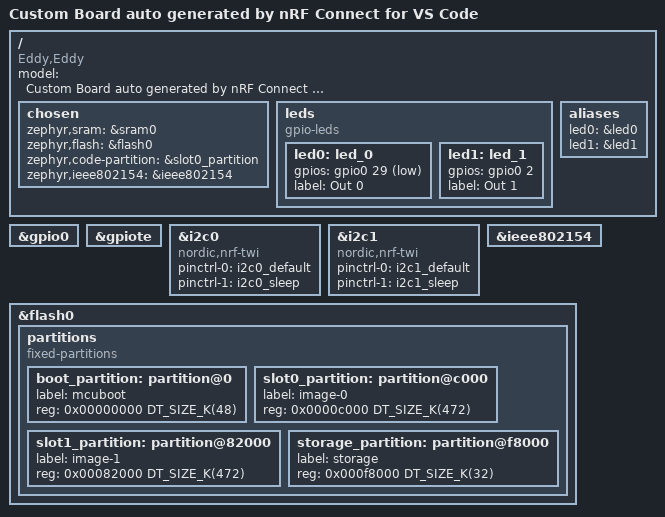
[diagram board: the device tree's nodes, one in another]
/dts-v1/;
#include <nordic/nrf52840_qiaa.dtsi>
#include "Eddy-pinctrl.dtsi"

/ {
	model = "Custom Board auto generated by nRF Connect for VS Code";
	compatible = "Eddy,Eddy";

	chosen {
		zephyr,sram = &sram0;
		zephyr,flash = &flash0;
		zephyr,code-partition = &slot0_partition;

		// zephyr,console = &uart0;
		// zephyr,shell-uart = &uart0;
		// zephyr,uart-mcumgr = &uart0;
		// zephyr,bt-mon-uart = &uart0;
		// zephyr,bt-c2h-uart = &uart0;
		zephyr,ieee802154 = &ieee802154;
	};

	leds {
		compatible = "gpio-leds";
		led0: led_0 {
			gpios = <&gpio0 29 GPIO_ACTIVE_LOW>;
			label = "Out 0";
		};
		led1: led_1 {
			gpios = <&gpio0 2 GPIO_ACTIVE_HIGH>;
			label = "Out 1";
		};
	};

	aliases {
		led0 = &led0;
		led1 = &led1;
		// i2s-codec-rx = &i2s0;
		// i2s-codec-tx = &i2s1;
	};
};

&gpio0 {
	status = "okay";
};

&gpiote {
	status = "okay";
};

&i2c0 {
	compatible = "nordic,nrf-twi";
	status = "okay";
	pinctrl-0 = <&i2c0_default>;
	pinctrl-1 = <&i2c0_sleep>;
	pinctrl-names = "default", "sleep";
};

&i2c1 {
	compatible = "nordic,nrf-twi";
	/* status = "okay"; */
	pinctrl-0 = <&i2c1_default>;
	pinctrl-1 = <&i2c1_sleep>;
	pinctrl-names = "default", "sleep";
};

&ieee802154 {
	status = "okay";
};

&flash0 {
	partitions {
		compatible = "fixed-partitions";
		#address-cells = <1>;
		#size-cells = <1>;

		boot_partition: partition@0 {
			label = "mcuboot";
			reg = <0x00000000 DT_SIZE_K(48)>;
		};

		slot0_partition: partition@c000 {
			label = "image-0";
			reg = <0x0000c000 DT_SIZE_K(472)>;
		};

		slot1_partition: partition@82000 {
			label = "image-1";
			reg = <0x00082000 DT_SIZE_K(472)>;
		};

		storage_partition: partition@f8000 {
			label = "storage";
			reg = <0x000f8000 DT_SIZE_K(32)>;
		};
	};
};

// &i2s0 {
// 	// mck-enabled;
// 	status = "okay";
// 	pinctrl-0 = <&i2s0_default>;
// 	pinctrl-names = "default";
// 	// Specify clock source?
// };
